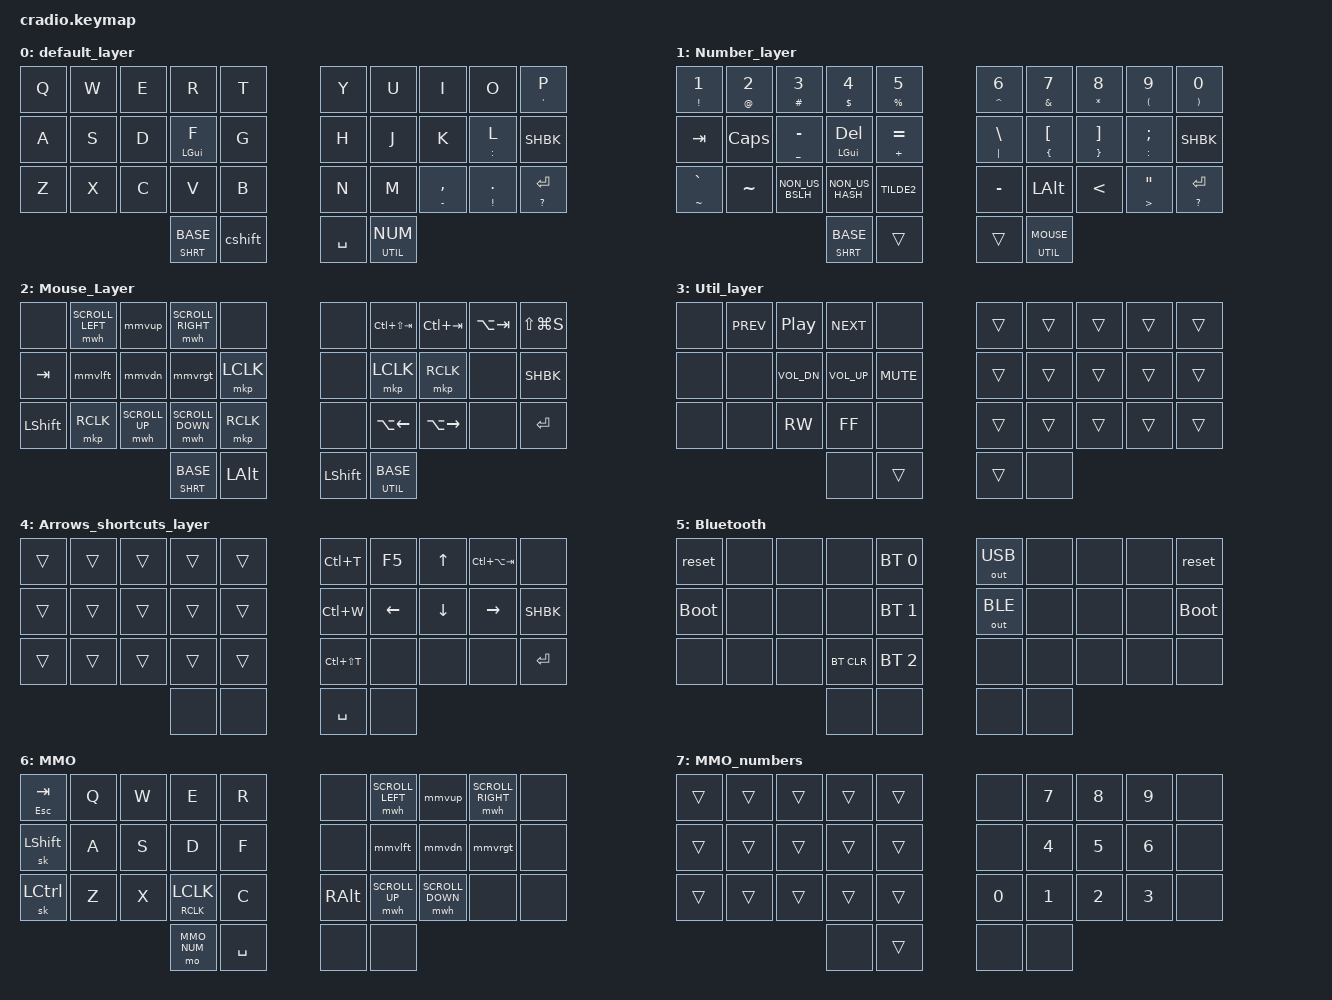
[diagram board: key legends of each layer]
// Copyright (c) 2022 The ZMK Contributors
// SPDX-License-Identifier: MIT

// Required dependencies, needs to be checked when adding something new
#include <behaviors.dtsi>
#include <dt-bindings/zmk/keys.h>
#include <dt-bindings/zmk/bt.h>
#include <dt-bindings/zmk/outputs.h>
#include <dt-bindings/zmk/mouse.h>

// Re-defining the move speed of the mouse emulation so the default is high
#define U_MOUSE_MOVE_MAX 1500
#undef MOVE_UP
#undef MOVE_DOWN
#undef MOVE_LEFT
#undef MOVE_RIGHT
#define MOVE_UP MOVE_VERT(-U_MOUSE_MOVE_MAX)
#define MOVE_DOWN MOVE_VERT(U_MOUSE_MOVE_MAX)
#define MOVE_LEFT MOVE_HOR(-U_MOUSE_MOVE_MAX)
#define MOVE_RIGHT MOVE_HOR(U_MOUSE_MOVE_MAX)

// Re-defining the scroll speed to be higher
#define U_MOUSE_SCROLL_MAX 100 
#undef SCROLL_UP
#undef SCROLL_DOWN
#undef SCROLL_LEFT
#undef SCROLL_RIGHT
#define SCROLL_UP SCROLL_VERT(U_MOUSE_SCROLL_MAX)
#define SCROLL_DOWN SCROLL_VERT(-U_MOUSE_SCROLL_MAX)
#define SCROLL_LEFT SCROLL_HOR(-U_MOUSE_SCROLL_MAX)
#define SCROLL_RIGHT SCROLL_HOR(U_MOUSE_SCROLL_MAX)

// Setting a custom second speed for mouse movement
#define U_MOUSE_MOVE_MAX2 750
#define MOVE_UP2 MOVE_VERT(-U_MOUSE_MOVE_MAX2)
#define MOVE_DOWN2 MOVE_VERT(U_MOUSE_MOVE_MAX2)
#define MOVE_LEFT2 MOVE_HOR(-U_MOUSE_MOVE_MAX2)
#define MOVE_RIGHT2 MOVE_HOR(U_MOUSE_MOVE_MAX2)

// Naming layers to keep things straight and organized
#define BASE 0
#define NUM 1
#define MOUSE 2
#define UTIL 3
#define SHRT 4
#define BLUE 5
#define MMO 6
#define MMO_NUM 7


// This section is adjusting included behaviors and declaring optional parameters

&mt {
    flavor = "tap-preferred";
    tapping_term_ms = <250>;
};

&sk {
    release-after-ms = <2000>;
    quick-release;
};

&mwh {
    acceleration-exponent=<1>;
};

&mmv {
    acceleration-exponent=<1>;
};

// This section is for custom combos
/ {
    combos {
        compatible = "zmk,combos";
	
//combo to reach the MMO layer from any other layer, activating it a second time returns you to the lower layers
        combo_MMO { 
            timeout-ms = <45>;
            key-positions = <30 33>;
	    layers = <0 1 2 3 4 6 7>;
            bindings = <&tog MMO>;
                  };

// Combo to reach BLUE layer for connection settings and bluetooth profiles (also for forcing BLE instead of USB and vice versa) toggles just like MMO
// Also set it so this combo should only work from base layer, so bail-out then BLUE.
         combo_BLUE { 
            timeout-ms = <50>;
            key-positions = <31 32>;
	    layers = <0>;
            bindings = <&tog BLUE>;
                  };
		  
// This is the "bail-out" combo if you're ever lost, this will take you back to the base layer
         combo_HOME { 
            timeout-ms = <75>;
            key-positions = <30 31>;
            bindings = <&to 0>;
                  };
            
	    };
                      
// This is where custom behaviors can be defined        
behaviors {

// This behavior lets me have a layer on holding a key, or move to another layer on tap.
moto: behavior_moto {
            compatible = "zmk,behavior-hold-tap";
            label = "moto";
            #binding-cells = <2>;
            flavor = "tap-preferred";
            tapping-term-ms = <250>;
            bindings = <&mo>, <&to>;
        };
        
// This behavior lets me use both left and right click on the same key, tap for left hold for right.	
DBCLK: behavior_DBCLK {
            compatible = "zmk,behavior-hold-tap";
            label = "DBCLK";
            #binding-cells = <2>;
            tapping-term-ms = <250>;
            quick-tap-ms = <150>;
            flavor = "tap-preferred";
            bindings = <&mkp>, <&mkp>;
        };
	
// These behaviors are the mod-morphs that should allow me different mouse speeds depending on if shift is being applied.
mmvup: Variable_Mouse_Move_Up {
            compatible = "zmk,behavior-mod-morph";
            label = "Variable_Mouse_Move_Up";
            #binding-cells = <0>;
            bindings = <&mmv MOVE_UP>, <&mmv MOVE_UP2>;
            mods = <(MOD_LSFT|MOD_RSFT)>;
        };
	
mmvdn: Variable_Mouse_Move_Down {
            compatible = "zmk,behavior-mod-morph";
            label = "Variable_Mouse_Move_Down";
            #binding-cells = <0>;
            bindings = <&mmv MOVE_DOWN>, <&mmv MOVE_DOWN2>;
            mods = <(MOD_LSFT|MOD_RSFT)>;
        };
	
mmvlft: Variable_Mouse_Move_Left {
            compatible = "zmk,behavior-mod-morph";
            label = "Variable_Mouse_Move_Left";
            #binding-cells = <0>;
            bindings = <&mmv MOVE_LEFT>, <&mmv MOVE_LEFT2>;
            mods = <(MOD_LSFT|MOD_RSFT)>;
        };
	
mmvrgt: Variable_Mouse_Move_Right {
            compatible = "zmk,behavior-mod-morph";
            label = "Variable_Mouse_Move_Right";
            #binding-cells = <0>;
            bindings = <&mmv MOVE_RIGHT>, <&mmv MOVE_RIGHT2>;
            mods = <(MOD_LSFT|MOD_RSFT)>;
        };
	
// This is the mod-morph for adding the forward slash to SHIFT BACKSPACE
SHBK: Shift_Back {
            compatible = "zmk,behavior-mod-morph";
            label = "Shift_Back";
            #binding-cells = <0>;
            bindings = <&kp BSPC>, <&kp SLASH>;
            mods = <(MOD_LSFT|MOD_RSFT)>;
        };

// This is the tap-dance behavior that lets me double tap shift to get a caps-lock effect
cshift: caps_shift {
            compatible = "zmk,behavior-tap-dance";
            label = "caps_shift";
            #binding-cells = <0>;
            tapping-term-ms = <100>;
            bindings = <&sk LSHIFT>, <&kp CAPS>;
        };
              
   };
    


/* Useful templates and references
blank template {
    bindings = <
//╭──────────┬──────────┬──────────┬──────────┬──────────╮   ╭──────────┬──────────┬──────────┬──────────┬──────────╮
//│          │          │          │          │          │   │          │          │          │          │          │
                                                                                                                     
//├──────────┼──────────┼──────────┼──────────┼──────────┤   ├──────────┼──────────┼──────────┼──────────┼──────────┤
//│          │          │          │          │          │   │          │          │          │          │          │
                                                                                                                     
//├──────────┼──────────┼──────────┼──────────┼──────────┤   ├──────────┼──────────┼──────────┼──────────┼──────────┤
//│          │          │          │          │          │   │          │          │          │          │          │
                                                                                                                     
//╰──────────┴──────────┴──────────┼──────────┼──────────┤   ├──────────┼──────────┼──────────┴──────────┴──────────╯
                                                                                    
//                                 ╰──────────┴──────────╯   ╰──────────┴──────────╯
            >;
        };
		
number reference {
    bindings = <
//╭──────────┬──────────┬──────────┬──────────┬──────────╮   ╭──────────┬──────────┬──────────┬──────────┬──────────╮
//│     0    │    1     │    2     │    3     │    4     │   │    5     │    6     │    7     │    8     │     9    │
                                                                                                                             
//├──────────┼──────────┼──────────┼──────────┼──────────┤   ├──────────┼──────────┼──────────┼──────────┼──────────┤
//│    10    │   11     │    12    │    13    │    14    │   │    15    │    16    │    17    │    18    │    19    │
                                                                                                                            
//├──────────┼──────────┼──────────┼──────────┼──────────┤   ├──────────┼──────────┼──────────┼──────────┼──────────┤
//│    20    │   21     │    22    │    23    │    24    │   │    25    │    26    │    27    │    28    │    29    │
                                                                                                                          
//╰──────────┴──────────┴──────────┼──────────┼──────────┤   ├──────────┼──────────┼──────────┴──────────┴──────────╯
                                        30         31             32         33    
//                                 ╰──────────┴──────────╯   ╰──────────┴──────────╯
            >;
        };

*/

// The actual keymap starts here

keymap {
        
        compatible = "zmk,keymap";
        
        default_layer { // BASE
            bindings = <
        //╭──────────┬──────────┬──────────┬──────────┬──────────╮   ╭──────────┬──────────┬──────────┬──────────┬──────────╮
        //│  Q       │  W       │  E       │  R       │  T       │   │  Y       │  U       │  I       │  O       │  P (')   │
            &kp Q      &kp W      &kp E      &kp R      &kp T          &kp Y      &kp U      &kp I      &kp O      &mt APOS P
        //├──────────┼──────────┼──────────┼──────────┼──────────┤   ├──────────┼──────────┼──────────┼──────────┼──────────┤
        //│  A       │  S       │  D       │  F (LGUI)│  G       │   │  H       │  J       │  K       │  L (:)   │ Backspace│
            &kp A      &kp S      &kp D     &mt LGUI F &kp G          &kp H      &kp J      &kp K      &mt COLON L &SHBK
        //├──────────┼──────────┼──────────┼──────────┼──────────┤   ├──────────┼──────────┼──────────┼──────────┼──────────┤
        //│  Z       │  X       │  C       │  V       │  B       │   │  N       │  M       │ , (-)    │ . (!)    │  Enter (?)
            &kp Z      &kp X      &kp C      &kp V      &kp B         &kp N     &kp M &mt MINUS COMMA &mt EXCL DOT &mt QMARK RET
        //╰──────────┴──────────┴──────────┼──────────┼──────────┤   ├──────────┼──────────┼──────────┴──────────┴──────────╯
                                       &moto SHRT BASE &cshift      &kp SPACE  &moto UTIL NUM
        //                                 ╰──────────┴──────────╯   ╰──────────┴──────────╯
            >;
        };

        Number_layer { // NUM
            bindings = <
        //╭──────────┬──────────┬──────────┬──────────┬──────────╮   ╭──────────┬──────────┬──────────┬──────────┬──────────╮
        //│ 1 (!)    │  2 (@)   │  3 (#)   │  4 ($)   │  5 (%)   │   │  6 (^)   │   7 (&)  │   8 (*)  │ 9 "("    │  0 ")"   │
         &mt EXCL N1 &mt AT N2  &mt HASH N3 &mt DLLR N4 &mt PRCNT N5 &mt CARET N6 &mt AMPS N7 &mt STAR N8 &mt LPAR N9 &mt RPAR N0   
        //├──────────┼──────────┼──────────┼──────────┼──────────┤   ├──────────┼──────────┼──────────┼──────────┼──────────┤
        //│          │          │          │          │          │   │          │          │          │          │          │
          &kp TAB  &kp CAPS  &mt UNDER MINUS  &mt LGUI DEL  &mt PLUS EQUAL &mt PIPE BACKSLASH &mt LBRC LBKT &mt RBRC RBKT &mt COLON SEMI  &SHBK 
        //├──────────┼──────────┼──────────┼──────────┼──────────┤   ├──────────┼──────────┼──────────┼──────────┼──────────┤
        //│          │          │          │          │          │   │          │          │          │          │          │
         &mt TILDE GRAVE    &kp TILDE 	&kp NON_US_BSLH &kp NON_US_HASH  &kp TILDE2 &kp MINUS &kp LALT &kp LESS_THAN &mt GREATER_THAN DQT  &mt QMARK RET   
        //╰──────────┴──────────┴──────────┼──────────┼──────────┤   ├──────────┼──────────┼──────────┴──────────┴──────────╯
                                          &moto SHRT BASE &trans        &trans   &moto UTIL MOUSE
        //                                 ╰──────────┴──────────╯   ╰──────────┴──────────╯
            >;
        };

        Mouse_Layer { // MOUSE
            bindings = <
        //╭──────────┬──────────┬──────────┬──────────┬──────────╮   ╭──────────┬──────────┬──────────┬──────────┬──────────╮
        //│          │          │          │          │          │   │          │          │          │          │          │
       &none &mwh SCROLL_LEFT &mmvup &mwh SCROLL_RIGHT &none         &none &kp LC(LS(TAB)) &kp LC(TAB) &kp LA(TAB) &kp LS(LG(S)) 
        //├──────────┼──────────┼──────────┼──────────┼──────────┤   ├──────────┼──────────┼──────────┼──────────┼──────────┤
        //│          │          │          │          │          │   │          │          │          │          │          │
          &kp TAB    &mmvlft    &mmvdn     &mmvrgt    &mkp LCLK           &none    &mkp LCLK    &mkp RCLK  &none      &SHBK
        //├──────────┼──────────┼──────────┼──────────┼──────────┤   ├──────────┼──────────┼──────────┼──────────┼──────────┤
        //│          │          │          │          │          │   │          │          │          │          │          │
         &kp LSHIFT &mkp RCLK &mwh SCROLL_UP &mwh SCROLL_DOWN &mkp RCLK  &none     &kp LA(LEFT)  &kp LA(RIGHT)  &none &kp RET
        //╰──────────┴──────────┴──────────┼──────────┼──────────┤   ├──────────┼──────────┼──────────┴──────────┴──────────╯
                                         &moto SHRT BASE &kp LALT     &kp LSHIFT &moto UTIL BASE
        //                                 ╰──────────┴──────────╯   ╰──────────┴──────────╯
            >;
        };

        Util_layer { // UTIL
            bindings = <
        //╭──────────┬──────────┬──────────┬──────────┬──────────╮   ╭──────────┬──────────┬──────────┬──────────┬──────────╮
        //│          │          │          │          │          |   │          │          │          │          │          |
            &none     &kp C_PREV  &kp C_PP   &kp C_NEXT &none           &trans     &trans     &trans      &trans     &trans
        //├──────────┼──────────┼──────────┼──────────┼──────────┤   ├──────────┼──────────┼──────────┼──────────┼──────────┤
        //│          │          │          │          │          │   │          │          │          │          │          │
             &none    &none &kp C_VOL_DN &kp C_VOL_UP  &kp C_MUTE       &trans     &trans     &trans      &trans     &trans
        //├──────────┼──────────┼──────────┼──────────┼──────────┤   ├──────────┼──────────┼──────────┼──────────┼──────────┤
        //│          │          │          │          │          │   │          │          │          │          │          │
            &none      &none       &kp C_RW  &kp C_FF   &none           &trans     &trans     &trans     &trans     &trans
        //╰──────────┴──────────┴──────────┼──────────┼──────────┤   ├──────────┼──────────┼──────────┴──────────┴──────────╯
                                             &none     &trans         &trans     &none
        //                                 ╰──────────┴──────────╯   ╰──────────┴──────────╯
            >;
        };
	
	Arrows_shortcuts_layer { // SHRT
            bindings = <
        //╭──────────┬──────────┬──────────┬──────────┬──────────╮   ╭──────────┬──────────┬──────────┬──────────┬──────────╮
        //│          │          │          │          │          │   │          │          │          │          │          │
            &trans     &trans     &trans      &trans     &trans        &kp LC(T)     &kp F5      &kp UP      &kp LC(LA(TAB))      &none      
        //├──────────┼──────────┼──────────┼──────────┼──────────┤   ├──────────┼──────────┼──────────┼──────────┼──────────┤
        //│          │          │          │          │          │   │          │          │          │          │          │
            &trans     &trans     &trans      &trans     &trans       &kp LC(W)       &kp LEFT   &kp DOWN  &kp RIGHT   &SHBK      
        //├──────────┼──────────┼──────────┼──────────┼──────────┤   ├──────────┼──────────┼──────────┼──────────┼──────────┤
        //│          │          │          │          │          │   │          │          │          │          │          │
            &trans     &trans     &trans      &trans     &trans       &kp LC(LS(T))      &none      &none      &none      &kp RET      
        //╰──────────┴──────────┴──────────┼──────────┼──────────┤   ├──────────┼──────────┼──────────┴──────────┴──────────╯
                                              &none      &none         &kp SPACE     &none                           
        //                                 ╰──────────┴──────────╯   ╰──────────┴──────────╯
            >;
        };
        
         Bluetooth { // BLUE
            bindings = <
        //╭──────────┬──────────┬──────────┬──────────┬──────────╮   ╭──────────┬──────────┬──────────┬──────────┬──────────╮
        //│ RESET    │          │          │          │PROFILE 0 │   │Force USB │          │          │          │  RESET   │
            &reset     &none      &none      &none     &bt BT_SEL 0   &out OUT_USB &none      &none      &none       &reset
        //├──────────┼──────────┼──────────┼──────────┼──────────┤   ├──────────┼──────────┼──────────┼──────────┼──────────┤
        //│BOOTLOADER│          │          │          │PROFILE 1 │   │Force BLE │          │          │          │BOOTLOADER│
          &bootloader  &none      &none      &none     &bt BT_SEL 1   &out OUT_BLE &none      &none      &none    &bootloader
        //├──────────┼──────────┼──────────┼──────────┼──────────┤   ├──────────┼──────────┼──────────┼──────────┼──────────┤
        //│          │          │          │ CLEAR BT │PROFILE 2 │   │          │          │          │          │          │
            &none      &none      &none     &bt BT_CLR &bt BT_SEL 2    &none      &none      &none      &none      &none 
        //╰──────────┴──────────┴──────────┼──────────┼──────────┤   ├──────────┼──────────┼──────────┴──────────┴──────────╯
                                             &none     &none         &none     &none
        //                                 ╰──────────┴──────────╯   ╰──────────┴──────────╯
            >;
        };
        
        MMO { // MMO
            bindings = <
        //╭──────────┬──────────┬──────────┬──────────┬──────────╮   ╭──────────┬──────────┬──────────┬──────────┬──────────╮
        //│ ESC/TAB  │   Q      │    W     │    E     │   R      │   │    ?     │ Scr Left │  mm Up   │Scr Right │    ?     │
           &mt ESC TAB  &kp Q      &kp W      &kp E      &kp R          &none   &mwh SCROLL_LEFT &mmvup &mwh SCROLL_RIGHT &none
        //├──────────┼──────────┼──────────┼──────────┼──────────┤   ├──────────┼──────────┼──────────┼──────────┼──────────┤
        //│   Shift  │   A      │    S     │    D     │    F     │   │    ?     │  mm Left │  mm Down │ mm Right │    ?     │
           &sk LSHIFT  &kp A      &kp S      &kp D      &kp F           &none    &mmvlft &mmvdn &mmvrgt &none 
        //├──────────┼──────────┼──────────┼──────────┼──────────┤   ├──────────┼──────────┼──────────┼──────────┼──────────┤
        //│  Control │   Z      │     X    │L & R clk │    C     │   │  ALT     │    ?     │  scr up  │  scr dn  │     ?    │
           &sk LCTL    &kp Z     &kp X   &DBCLK RCLK LCLK  &kp C      &kp RALT &mwh SCROLL_UP &mwh SCROLL_DOWN &none &none 
        //╰──────────┴──────────┴──────────┼──────────┼──────────┤   ├──────────┼──────────┼──────────┴──────────┴──────────╯
                                            &mo MMO_NUM  &kp SPACE     &none       &none   
        //                                 ╰──────────┴──────────╯   ╰──────────┴──────────╯
            >;
        };
        
        MMO_numbers { // MMO_NUM
            bindings = <
        //╭──────────┬──────────┬──────────┬──────────┬──────────╮   ╭──────────┬──────────┬──────────┬──────────┬──────────╮
        //│          │          │          │          │          │   │          │     7    │     8    │    9     │          │
              &trans   &trans     &trans     &trans      &trans          &none     &kp N7     &kp N8     &kp N9    &none     
        //├──────────┼──────────┼──────────┼──────────┼──────────┤   ├──────────┼──────────┼──────────┼──────────┼──────────┤
        //│          │          │          │          │          │   │          │     4    │      5   │     6    │          │
              &trans   &trans     &trans      &trans     &trans           &none    &kp N4     &kp N5     &kp N6      &none  
        //├──────────┼──────────┼──────────┼──────────┼──────────┤   ├──────────┼──────────┼──────────┼──────────┼──────────┤
        //│          │          │          │          │          │   │          │     1    │     2    │    3     │          │
              &trans    &trans     &trans     &trans     &trans         &kp N0      &kp N1    &kp N2     &kp N3      &none   
        //╰──────────┴──────────┴──────────┼──────────┼──────────┤   ├──────────┼──────────┼──────────┴──────────┴──────────╯
                                            &none      &trans          &none       &none                   
        //                                 ╰──────────┴──────────╯   ╰──────────┴──────────╯
            >;
        };
    };
};
